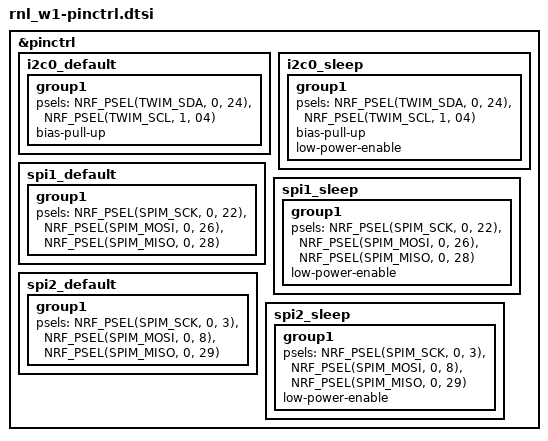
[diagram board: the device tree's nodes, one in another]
/*
 * Copyright (c) 2023 RedNodeLabs.
 * SPDX-License-Identifier: Apache-2.0
 */

&pinctrl {
	i2c0_default: i2c0_default {
		group1 {
			psels = <NRF_PSEL(TWIM_SDA, 0, 24)>,
				<NRF_PSEL(TWIM_SCL, 1, 04)>;
			bias-pull-up;
		};
	};

	i2c0_sleep: i2c0_sleep {
		group1 {
			psels = <NRF_PSEL(TWIM_SDA, 0, 24)>,
				<NRF_PSEL(TWIM_SCL, 1, 04)>;
			bias-pull-up;
			low-power-enable;
		};
	};

	spi1_default: spi1_default {
		group1 {
			psels = <NRF_PSEL(SPIM_SCK, 0, 22)>,
				<NRF_PSEL(SPIM_MOSI, 0, 26)>,
				<NRF_PSEL(SPIM_MISO, 0, 28)>;
		};
	};

	spi1_sleep: spi1_sleep {
		group1 {
			psels = <NRF_PSEL(SPIM_SCK, 0, 22)>,
				<NRF_PSEL(SPIM_MOSI, 0, 26)>,
				<NRF_PSEL(SPIM_MISO, 0, 28)>;
			low-power-enable;
		};
	};

	spi2_default: spi2_default {
		group1 {
			psels = <NRF_PSEL(SPIM_SCK, 0, 3)>,
			        <NRF_PSEL(SPIM_MOSI, 0, 8)>,
			        <NRF_PSEL(SPIM_MISO, 0, 29)>;
		};
	};

	spi2_sleep: spi2_sleep {
		group1 {
			psels = <NRF_PSEL(SPIM_SCK, 0, 3)>,
			        <NRF_PSEL(SPIM_MOSI, 0, 8)>,
			        <NRF_PSEL(SPIM_MISO, 0, 29)>;
			low-power-enable;
		};
	};
};
